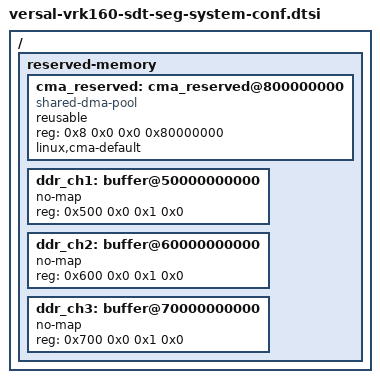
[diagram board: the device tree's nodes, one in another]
/ {
	reserved-memory {
		#address-cells = <2>;
		#size-cells = <2>;
		ranges;
		cma_reserved: cma_reserved@800000000 {
			compatible = "shared-dma-pool";
			reusable;
			reg = <0x8 0x0 0x0 0x80000000>;
			linux,cma-default;
		};
		ddr_ch1: buffer@50000000000 {
			no-map;
			reg = <0x500 0x0 0x1 0x0>;
		};
		ddr_ch2: buffer@60000000000 {
			no-map;
			reg = <0x600 0x0 0x1 0x0>;
		};
		ddr_ch3: buffer@70000000000 {
			no-map;
			reg = <0x700 0x0 0x1 0x0>;
		};
	};
};

